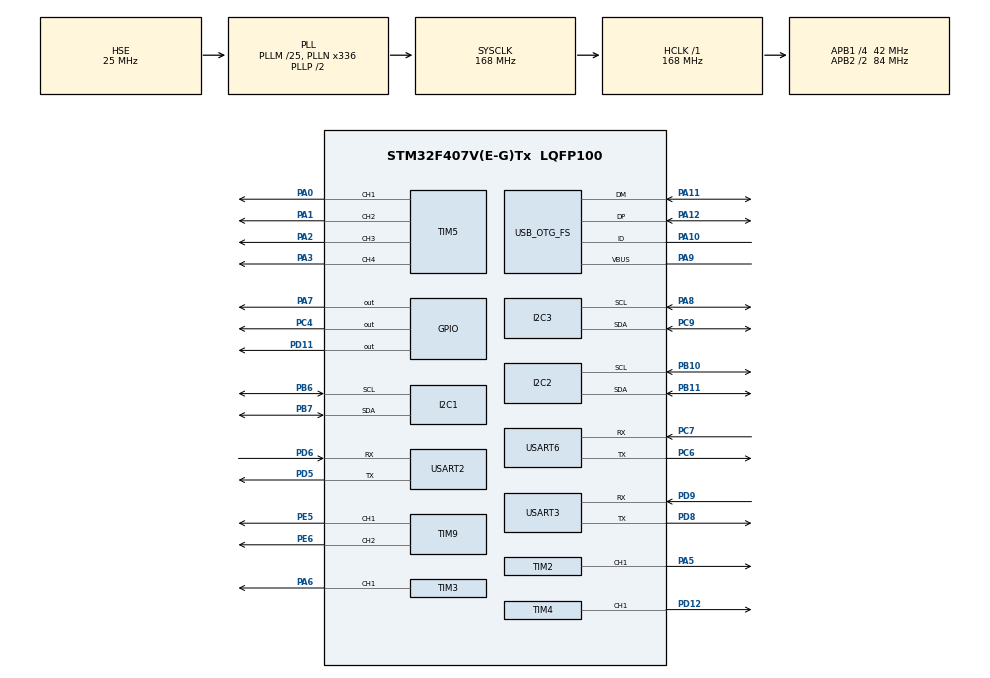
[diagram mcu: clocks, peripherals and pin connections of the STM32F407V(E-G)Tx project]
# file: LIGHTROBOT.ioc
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Mcu.Family=STM32F4
Mcu.Name=STM32F407V(E-G)Tx
Mcu.Package=LQFP100
NVIC.PriorityGroup=NVIC_PRIORITYGROUP_4
NVIC.USART2_IRQn=true\:0\:0\:false\:false\:true\:true\:true\:true
NVIC.USART3_IRQn=true\:0\:0\:false\:false\:true\:true\:true\:true
NVIC.USART6_IRQn=true\:0\:0\:false\:false\:true\:true\:true\:true
PA0-WKUP.Signal=S_TIM5_CH1
PA1.Signal=S_TIM5_CH2
PA10.Mode=OTG/Dual_Role_Device
PA10.Signal=USB_OTG_FS_ID
PA11.Mode=OTG/Dual_Role_Device
PA11.Signal=USB_OTG_FS_DM
PA12.Mode=OTG/Dual_Role_Device
PA12.Signal=USB_OTG_FS_DP
PA13.Mode=Serial_Wire
PA13.Signal=SYS_JTMS-SWDIO
PA14.Mode=Serial_Wire
PA14.Signal=SYS_JTCK-SWCLK
PA2.Signal=S_TIM5_CH3
PA3.Signal=S_TIM5_CH4
PA5.Signal=S_TIM2_CH1_ETR
PA6.Signal=S_TIM3_CH1
PA7.Signal=GPIO_Output
PA8.Mode=I2C
PA8.Signal=I2C3_SCL
PA9.Mode=Activate_VBUS
PA9.Signal=USB_OTG_FS_VBUS
PB10.Mode=I2C
PB10.Signal=I2C2_SCL
PB11.Mode=I2C
PB11.Signal=I2C2_SDA
PB6.Mode=I2C
PB6.Signal=I2C1_SCL
PB7.Mode=I2C
PB7.Signal=I2C1_SDA
PC4.Signal=GPIO_Output
PC6.Mode=Asynchronous
PC6.Signal=USART6_TX
PC7.Mode=Asynchronous
PC7.Signal=USART6_RX
PC9.Mode=I2C
PC9.Signal=I2C3_SDA
PD11.Signal=GPIO_Output
PD12.Signal=S_TIM4_CH1
PD5.Mode=Asynchronous
PD5.Signal=USART2_TX
PD6.Mode=Asynchronous
PD6.Signal=USART2_RX
PD8.Mode=Asynchronous
PD8.Signal=USART3_TX
PD9.Mode=Asynchronous
PD9.Signal=USART3_RX
PE5.Signal=S_TIM9_CH1
PE6.Signal=S_TIM9_CH2
PH0-OSC_IN.Mode=HSE-External-Oscillator
PH0-OSC_IN.Signal=RCC_OSC_IN
PH1-OSC_OUT.Mode=HSE-External-Oscillator
PH1-OSC_OUT.Signal=RCC_OSC_OUT
ProjectManager.HeapSize=0x200
ProjectManager.StackSize=0x400
ProjectManager.TargetToolchain=MDK-ARM V5.32
RCC.48MHZClocksFreq_Value=48000000
RCC.AHBFreq_Value=168000000
RCC.APB1CLKDivider=RCC_HCLK_DIV4
RCC.APB1Freq_Value=42000000
RCC.APB1TimFreq_Value=84000000
RCC.APB2CLKDivider=RCC_HCLK_DIV2
RCC.APB2Freq_Value=84000000
RCC.APB2TimFreq_Value=168000000
RCC.CortexFreq_Value=168000000
RCC.HCLKFreq_Value=168000000
RCC.HSE_VALUE=25000000
RCC.HSI_VALUE=16000000
RCC.LSE_VALUE=32768
RCC.PLLM=25
RCC.PLLN=336
RCC.PLLQ=7
RCC.SYSCLKFreq_VALUE=168000000
RCC.SYSCLKSource=RCC_SYSCLKSOURCE_PLLCLK
RCC.VCOOutputFreq_Value=336000000
SH.S_TIM2_CH1_ETR.0=TIM2_CH1,PWM Generation1 CH1
SH.S_TIM3_CH1.0=TIM3_CH1,PWM Generation1 CH1
SH.S_TIM4_CH1.0=TIM4_CH1,PWM Generation1 CH1
SH.S_TIM5_CH1.0=TIM5_CH1,PWM Generation1 CH1
SH.S_TIM5_CH2.0=TIM5_CH2,PWM Generation2 CH2
SH.S_TIM5_CH3.0=TIM5_CH3,PWM Generation3 CH3
SH.S_TIM5_CH4.0=TIM5_CH4,PWM Generation4 CH4
SH.S_TIM9_CH1.0=TIM9_CH1,PWM Generation1 CH1
SH.S_TIM9_CH2.0=TIM9_CH2,PWM Generation2 CH2
TIM2.Channel-PWM\ Generation1\ CH1=TIM_CHANNEL_1
TIM3.Channel-PWM\ Generation1\ CH1=TIM_CHANNEL_1
TIM4.Channel-PWM\ Generation1\ CH1=TIM_CHANNEL_1
TIM5.Channel-PWM\ Generation1\ CH1=TIM_CHANNEL_1
TIM5.Channel-PWM\ Generation2\ CH2=TIM_CHANNEL_2
TIM5.Channel-PWM\ Generation3\ CH3=TIM_CHANNEL_3
TIM5.Channel-PWM\ Generation4\ CH4=TIM_CHANNEL_4
TIM9.Channel-PWM\ Generation1\ CH1=TIM_CHANNEL_1
TIM9.Channel-PWM\ Generation2\ CH2=TIM_CHANNEL_2
USART2.VirtualMode=VM_ASYNC
USART3.VirtualMode=VM_ASYNC
USART6.VirtualMode=VM_ASYNC
board=custom

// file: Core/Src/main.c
/* USER CODE BEGIN Header */
/**
  ******************************************************************************
  * @file           : main.c
  * @brief          : Main program body
  ******************************************************************************
  * @attention
  *
  * Copyright (c) 2026 STMicroelectronics.
  * All rights reserved.
  *
  * This software is licensed under terms that can be found in the LICENSE file
  * in the root directory of this software component.
  * If no LICENSE file comes with this software, it is provided AS-IS.
  *
  ******************************************************************************
  */
/* USER CODE END Header */
#include "main.h"
#include "i2c.h"
#include "tim.h"
#include "usart.h"
#include "usb_otg.h"
#include "gpio.h"

/* USER CODE BEGIN Includes */
#include "huidu.h"
#include "test.h"
#include "tcs34725.h"

/* USER CODE END Includes */

void SystemClock_Config(void);

int main(void)
{

  /* MCU Configuration--------------------------------------------------------*/

  /* Reset of all peripherals, Initializes the Flash interface and the Systick. */
  HAL_Init();

  /* Configure the system clock */
  SystemClock_Config();

  /* Initialize all configured peripherals */
  MX_GPIO_Init();
  MX_I2C1_Init();
  MX_I2C2_Init();
  MX_I2C3_Init();
  MX_TIM2_Init();
  MX_TIM3_Init();
  MX_TIM4_Init();
  MX_TIM5_Init();
  MX_TIM9_Init();
  MX_USART2_UART_Init();
  MX_USART3_UART_Init();
  MX_USART6_UART_Init();
  MX_USB_OTG_FS_USB_Init();
  /* USER CODE BEGIN 2 */
  OLED_Init();
  TCS34725_Init();
  /* USER CODE END 2 */

  /* Infinite loop */
  while (1)
  {

    /* USER CODE BEGIN 3 */
    Test_All();
  }
  /* USER CODE END 3 */
}

void SystemClock_Config(void)
{
  RCC_OscInitTypeDef RCC_OscInitStruct = {0};
  RCC_ClkInitTypeDef RCC_ClkInitStruct = {0};

  /** Configure the main internal regulator output voltage
  */
  __HAL_RCC_PWR_CLK_ENABLE();
  __HAL_PWR_VOLTAGESCALING_CONFIG(PWR_REGULATOR_VOLTAGE_SCALE1);

  /** Initializes the RCC Oscillators according to the specified parameters
  * in the RCC_OscInitTypeDef structure.
  */
  RCC_OscInitStruct.OscillatorType = RCC_OSCILLATORTYPE_HSE;
  RCC_OscInitStruct.HSEState = RCC_HSE_ON;
  RCC_OscInitStruct.PLL.PLLState = RCC_PLL_ON;
  RCC_OscInitStruct.PLL.PLLSource = RCC_PLLSOURCE_HSE;
  RCC_OscInitStruct.PLL.PLLM = 25;
  RCC_OscInitStruct.PLL.PLLN = 336;
  RCC_OscInitStruct.PLL.PLLP = RCC_PLLP_DIV2;
  RCC_OscInitStruct.PLL.PLLQ = 7;
  if (HAL_RCC_OscConfig(&RCC_OscInitStruct) != HAL_OK)
  {
    Error_Handler();
  }

  /** Initializes the CPU, AHB and APB buses clocks
  */
  RCC_ClkInitStruct.ClockType = RCC_CLOCKTYPE_HCLK|RCC_CLOCKTYPE_SYSCLK
                              |RCC_CLOCKTYPE_PCLK1|RCC_CLOCKTYPE_PCLK2;
  RCC_ClkInitStruct.SYSCLKSource = RCC_SYSCLKSOURCE_PLLCLK;
  RCC_ClkInitStruct.AHBCLKDivider = RCC_SYSCLK_DIV1;
  RCC_ClkInitStruct.APB1CLKDivider = RCC_HCLK_DIV4;
  RCC_ClkInitStruct.APB2CLKDivider = RCC_HCLK_DIV2;

  if (HAL_RCC_ClockConfig(&RCC_ClkInitStruct, FLASH_LATENCY_5) != HAL_OK)
  {
    Error_Handler();
  }
}

/* USER CODE BEGIN 4 */

/**
  * @brief  HAL UART 接收完成回调
  * @param  huart: UART 句柄指针
  * @retval None
  */
void HAL_UART_RxCpltCallback(UART_HandleTypeDef *huart)
{
    extern uint8_t huidu_rx_byte;
    if (huart->Instance == USART6)
    {
        HUIDU_RxCallback(huidu_rx_byte);
        HAL_UART_Receive_IT(&huart6, &huidu_rx_byte, 1);
    }
}

/* USER CODE END 4 */

void Error_Handler(void)
{
  __disable_irq();
  while (1)
  {
  }
}
